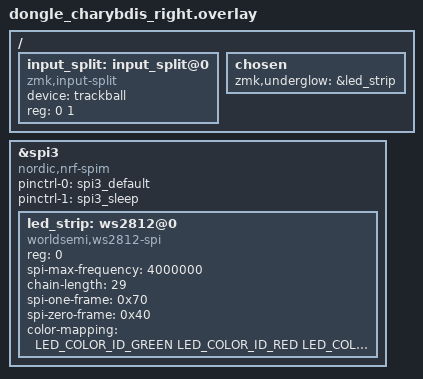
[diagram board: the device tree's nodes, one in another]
/*
 * Copyright (c) 2024 The ZMK Contributors
 * SPDX-License-Identifier: MIT
 * 
 * Charybdis right keyboard - Peripheral mode (for use with dongle)
 * Forwards trackball input to central device
 */

#include "charybdis_right_common.dtsi"

/ {
    // Forward trackball input from peripheral to central (dongle)
    input_split: input_split@0 {
        compatible = "zmk,input-split";
        status = "okay";
        device = <&trackball>;
        reg = <0 1>;  // address 0, size 1
    };
};

&spi3 {
    compatible = "nordic,nrf-spim";
    status = "okay";

    pinctrl-0 = <&spi3_default>;
    pinctrl-1 = <&spi3_sleep>;
    pinctrl-names = "default", "sleep";

    led_strip: ws2812@0 {
        compatible = "worldsemi,ws2812-spi";

        /* SPI */
        reg = <0>; /* ignored, but necessary for SPI bindings */
        spi-max-frequency = <4000000>;

        /* WS2812 */
        chain-length = <29>; /* arbitrary; change at will */
        spi-one-frame = <0x70>;
        spi-zero-frame = <0x40>;

        color-mapping = <LED_COLOR_ID_GREEN LED_COLOR_ID_RED LED_COLOR_ID_BLUE>;
    };
};

/ {
    chosen {
        zmk,underglow = &led_strip;
    };
};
